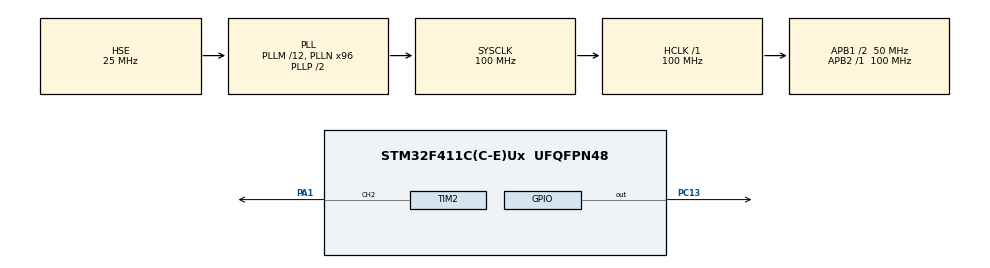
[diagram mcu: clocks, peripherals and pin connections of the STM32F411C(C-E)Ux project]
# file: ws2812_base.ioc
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Dma.Request0=TIM2_CH2/CH4
Dma.TIM2_CH2/CH4.0.Direction=DMA_MEMORY_TO_PERIPH
Dma.TIM2_CH2/CH4.0.FIFOMode=DMA_FIFOMODE_DISABLE
Dma.TIM2_CH2/CH4.0.Instance=DMA1_Stream6
Dma.TIM2_CH2/CH4.0.MemDataAlignment=DMA_MDATAALIGN_WORD
Dma.TIM2_CH2/CH4.0.MemInc=DMA_MINC_ENABLE
Dma.TIM2_CH2/CH4.0.Mode=DMA_CIRCULAR
Dma.TIM2_CH2/CH4.0.PeriphDataAlignment=DMA_PDATAALIGN_WORD
Dma.TIM2_CH2/CH4.0.PeriphInc=DMA_PINC_DISABLE
Dma.TIM2_CH2/CH4.0.Priority=DMA_PRIORITY_LOW
Mcu.Family=STM32F4
Mcu.Name=STM32F411C(C-E)Ux
Mcu.Package=UFQFPN48
NVIC.DMA1_Stream6_IRQn=true\:0\:0\:false\:false\:true\:false\:true
NVIC.PriorityGroup=NVIC_PRIORITYGROUP_4
NVIC.TIM5_IRQn=true\:0\:0\:false\:false\:true\:true\:true
PA1.Signal=S_TIM2_CH2
PA13.Mode=Serial_Wire
PA13.Signal=SYS_JTMS-SWDIO
PA14.Mode=Serial_Wire
PA14.Signal=SYS_JTCK-SWCLK
PC13-ANTI_TAMP.Signal=GPIO_Output
PH0\ -\ OSC_IN.Mode=HSE-External-Oscillator
PH0\ -\ OSC_IN.Signal=RCC_OSC_IN
PH1\ -\ OSC_OUT.Mode=HSE-External-Oscillator
PH1\ -\ OSC_OUT.Signal=RCC_OSC_OUT
ProjectManager.HeapSize=0x200
ProjectManager.StackSize=0x400
ProjectManager.TargetToolchain=STM32CubeIDE
RCC.48MHZClocksFreq_Value=50000000
RCC.AHBFreq_Value=100000000
RCC.APB1CLKDivider=RCC_HCLK_DIV2
RCC.APB1Freq_Value=50000000
RCC.APB1TimFreq_Value=100000000
RCC.APB2Freq_Value=100000000
RCC.APB2TimFreq_Value=100000000
RCC.CortexFreq_Value=100000000
RCC.HCLKFreq_Value=100000000
RCC.HSE_VALUE=25000000
RCC.HSI_VALUE=16000000
RCC.LSE_VALUE=32768
RCC.PLLM=12
RCC.PLLN=96
RCC.PLLSourceVirtual=RCC_PLLSOURCE_HSE
RCC.SYSCLKFreq_VALUE=100000000
RCC.SYSCLKSource=RCC_SYSCLKSOURCE_PLLCLK
RCC.VCOOutputFreq_Value=200000000
SH.S_TIM2_CH2.0=TIM2_CH2,PWM Generation2 CH2
TIM2.Channel-PWM\ Generation2\ CH2=TIM_CHANNEL_2
TIM2.Period=0
TIM5.AutoReloadPreload=TIM_AUTORELOAD_PRELOAD_ENABLE
TIM5.ClockDivision=TIM_CLOCKDIVISION_DIV1
TIM5.Period=10-1
TIM5.Prescaler=10000-1
VP_TIM2_VS_ClockSourceINT.Mode=Internal
VP_TIM5_VS_ClockSourceINT.Mode=Internal
board=custom

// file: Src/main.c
/* USER CODE BEGIN Header */
/**
  ******************************************************************************
  * @file           : main.c
  * @brief          : Main program body
  ******************************************************************************
  * @attention
  *
  * <h2><center>&copy; Copyright (c) 2021 STMicroelectronics.
  * All rights reserved.</center></h2>
  *
  * This software component is licensed by ST under BSD 3-Clause license,
  * the "License"; You may not use this file except in compliance with the
  * License. You may obtain a copy of the License at:
  *                        opensource.org/licenses/BSD-3-Clause
  *
  ******************************************************************************
  */
/* USER CODE END Header */
#include "main.h"

/* USER CODE BEGIN Includes */
#include "initialize.h"
#include "periphery.h"
#include <array>
#include "AddressableLedStrip.h"
/* USER CODE END Includes */

TIM_HandleTypeDef htim2;
TIM_HandleTypeDef htim5;
DMA_HandleTypeDef hdma_tim2_ch2_ch4;

void SystemClock_Config(void);
static void MX_GPIO_Init(void);
static void MX_DMA_Init(void);
static void MX_TIM2_Init(void);
static void MX_TIM5_Init(void);

/* USER CODE BEGIN 0 */

void HAL_TIM_PWM_PulseFinishedCallback(TIM_HandleTypeDef *htim)
{
//    HAL_TIM_PWM_Stop_DMA(&htim2,TIM_CHANNEL_2);
    Periphery::AddressableLedStrip::Reset();
}

void HAL_TIM_PeriodElapsedCallback(TIM_HandleTypeDef* htim)
{
    if(htim == &htim5)
    {
        System::GetTimerFactory().Decrement(1);
    }
}
/* USER CODE END 0 */

int main(void)
{

  /* MCU Configuration--------------------------------------------------------*/

  /* Reset of all peripherals, Initializes the Flash interface and the Systick. */
  HAL_Init();

  /* Configure the system clock */
  SystemClock_Config();

  /* Initialize all configured peripherals */
  MX_GPIO_Init();
  MX_DMA_Init();
  MX_TIM2_Init();
  MX_TIM5_Init();
  /* USER CODE BEGIN 2 */

    srand(0);

    System::Init();
    auto& led_update_timer = System::GetTimerFactory().CreateFineTimer(20);
    LedStrip led_strip(
            led_update_timer,
            [](uint32_t* data, uint16_t len)
            {
                Periphery::AddressableLedStrip::Update(data, len);
            }
    );
    led_strip.SetLedOnMask(0xFF);

  /* USER CODE END 2 */

  /* Infinite loop */
  /* USER CODE BEGIN WHILE */
  while (1)
  {
    System::GetTimerFactory().NotifySubscribers();

      led_strip.SetIntervalColor(RGBColor{static_cast<uint8_t>(rand()%255),0,0}, 0, 10);
      HAL_Delay(200);
    /* USER CODE END WHILE */

  }
}

void SystemClock_Config(void)
{
  RCC_OscInitTypeDef RCC_OscInitStruct = {0};
  RCC_ClkInitTypeDef RCC_ClkInitStruct = {0};

  /** Configure the main internal regulator output voltage
  */
  __HAL_RCC_PWR_CLK_ENABLE();
  __HAL_PWR_VOLTAGESCALING_CONFIG(PWR_REGULATOR_VOLTAGE_SCALE1);
  /** Initializes the RCC Oscillators according to the specified parameters
  * in the RCC_OscInitTypeDef structure.
  */
  RCC_OscInitStruct.OscillatorType = RCC_OSCILLATORTYPE_HSE;
  RCC_OscInitStruct.HSEState = RCC_HSE_ON;
  RCC_OscInitStruct.PLL.PLLState = RCC_PLL_ON;
  RCC_OscInitStruct.PLL.PLLSource = RCC_PLLSOURCE_HSE;
  RCC_OscInitStruct.PLL.PLLM = 12;
  RCC_OscInitStruct.PLL.PLLN = 96;
  RCC_OscInitStruct.PLL.PLLP = RCC_PLLP_DIV2;
  RCC_OscInitStruct.PLL.PLLQ = 4;
  if (HAL_RCC_OscConfig(&RCC_OscInitStruct) != HAL_OK)
  {
    Error_Handler();
  }
  /** Initializes the CPU, AHB and APB buses clocks
  */
  RCC_ClkInitStruct.ClockType = RCC_CLOCKTYPE_HCLK|RCC_CLOCKTYPE_SYSCLK
                              |RCC_CLOCKTYPE_PCLK1|RCC_CLOCKTYPE_PCLK2;
  RCC_ClkInitStruct.SYSCLKSource = RCC_SYSCLKSOURCE_PLLCLK;
  RCC_ClkInitStruct.AHBCLKDivider = RCC_SYSCLK_DIV1;
  RCC_ClkInitStruct.APB1CLKDivider = RCC_HCLK_DIV2;
  RCC_ClkInitStruct.APB2CLKDivider = RCC_HCLK_DIV1;

  if (HAL_RCC_ClockConfig(&RCC_ClkInitStruct, FLASH_LATENCY_3) != HAL_OK)
  {
    Error_Handler();
  }
}

static void MX_TIM2_Init(void)
{

  TIM_ClockConfigTypeDef sClockSourceConfig = {0};
  TIM_MasterConfigTypeDef sMasterConfig = {0};
  TIM_OC_InitTypeDef sConfigOC = {0};

  htim2.Instance = TIM2;
  htim2.Init.Prescaler = 0;
  htim2.Init.CounterMode = TIM_COUNTERMODE_UP;
  htim2.Init.Period = 0;
  htim2.Init.ClockDivision = TIM_CLOCKDIVISION_DIV1;
  htim2.Init.AutoReloadPreload = TIM_AUTORELOAD_PRELOAD_DISABLE;
  if (HAL_TIM_Base_Init(&htim2) != HAL_OK)
  {
    Error_Handler();
  }
  sClockSourceConfig.ClockSource = TIM_CLOCKSOURCE_INTERNAL;
  if (HAL_TIM_ConfigClockSource(&htim2, &sClockSourceConfig) != HAL_OK)
  {
    Error_Handler();
  }
  if (HAL_TIM_PWM_Init(&htim2) != HAL_OK)
  {
    Error_Handler();
  }
  sMasterConfig.MasterOutputTrigger = TIM_TRGO_RESET;
  sMasterConfig.MasterSlaveMode = TIM_MASTERSLAVEMODE_DISABLE;
  if (HAL_TIMEx_MasterConfigSynchronization(&htim2, &sMasterConfig) != HAL_OK)
  {
    Error_Handler();
  }
  sConfigOC.OCMode = TIM_OCMODE_PWM1;
  sConfigOC.Pulse = 0;
  sConfigOC.OCPolarity = TIM_OCPOLARITY_HIGH;
  sConfigOC.OCFastMode = TIM_OCFAST_DISABLE;
  if (HAL_TIM_PWM_ConfigChannel(&htim2, &sConfigOC, TIM_CHANNEL_2) != HAL_OK)
  {
    Error_Handler();
  }
  HAL_TIM_MspPostInit(&htim2);

}

static void MX_TIM5_Init(void)
{

  TIM_ClockConfigTypeDef sClockSourceConfig = {0};
  TIM_MasterConfigTypeDef sMasterConfig = {0};

  htim5.Instance = TIM5;
  htim5.Init.Prescaler = 10000-1;
  htim5.Init.CounterMode = TIM_COUNTERMODE_UP;
  htim5.Init.Period = 10-1;
  htim5.Init.ClockDivision = TIM_CLOCKDIVISION_DIV1;
  htim5.Init.AutoReloadPreload = TIM_AUTORELOAD_PRELOAD_ENABLE;
  if (HAL_TIM_Base_Init(&htim5) != HAL_OK)
  {
    Error_Handler();
  }
  sClockSourceConfig.ClockSource = TIM_CLOCKSOURCE_INTERNAL;
  if (HAL_TIM_ConfigClockSource(&htim5, &sClockSourceConfig) != HAL_OK)
  {
    Error_Handler();
  }
  sMasterConfig.MasterOutputTrigger = TIM_TRGO_RESET;
  sMasterConfig.MasterSlaveMode = TIM_MASTERSLAVEMODE_DISABLE;
  if (HAL_TIMEx_MasterConfigSynchronization(&htim5, &sMasterConfig) != HAL_OK)
  {
    Error_Handler();
  }

}

static void MX_DMA_Init(void)
{

  /* DMA controller clock enable */
  __HAL_RCC_DMA1_CLK_ENABLE();

  /* DMA interrupt init */
  /* DMA1_Stream6_IRQn interrupt configuration */
  HAL_NVIC_SetPriority(DMA1_Stream6_IRQn, 0, 0);
  HAL_NVIC_EnableIRQ(DMA1_Stream6_IRQn);

}

static void MX_GPIO_Init(void)
{
  GPIO_InitTypeDef GPIO_InitStruct = {0};

  /* GPIO Ports Clock Enable */
  __HAL_RCC_GPIOC_CLK_ENABLE();
  __HAL_RCC_GPIOH_CLK_ENABLE();
  __HAL_RCC_GPIOA_CLK_ENABLE();

  /*Configure GPIO pin Output Level */
  HAL_GPIO_WritePin(GPIOC, GPIO_PIN_13, GPIO_PIN_RESET);

  /*Configure GPIO pin : PC13 */
  GPIO_InitStruct.Pin = GPIO_PIN_13;
  GPIO_InitStruct.Mode = GPIO_MODE_OUTPUT_PP;
  GPIO_InitStruct.Pull = GPIO_NOPULL;
  GPIO_InitStruct.Speed = GPIO_SPEED_FREQ_LOW;
  HAL_GPIO_Init(GPIOC, &GPIO_InitStruct);

}

void Error_Handler(void)
{
  __disable_irq();
  while (1)
  {
  }
}
